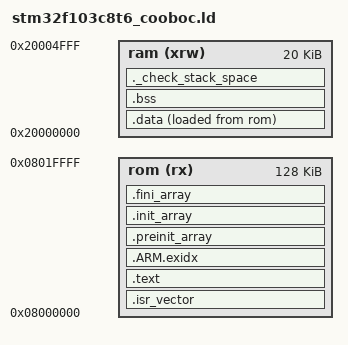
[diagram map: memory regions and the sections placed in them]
/*
* STM32 Discovery Linker Script
*/



ENTRY(Reset_Handler)

MEMORY
{
  rom (rx)      : ORIGIN = 0x08000000, LENGTH = 128K
  ram (xrw)     : ORIGIN = 0x20000000, LENGTH = 20K
}

_estack = 0x20005000;    /* bottom of 20k sram */
/*_estack = ORIGIN(RAM)+LENGTH(RAM);*/
_minimum_stack_size = 0x100; /* 256 bytes miniumum stack size */

SECTIONS
{
    /* Reset and ISR vectors */
    .isr_vector :
    {
        __isr_vector_start__ = .;
        KEEP(*(.isr_vector)) /* without 'KEEP' the garbage collector discards this section */
        ASSERT(. != __isr_vector_start__, "The .isr_vector section is empty");
    } >rom

    /*text sction, code and read only data */
  .text :
  {
    KEEP(*(.isr_vector))
    *(.text)           /* .text sections (code) */
    *(.text*)          /* .text* sections (code) */
    *(.rodata)         /* .rodata sections (constants, strings, etc.) */
    *(.rodata*)        /* .rodata* sections (constants, strings, etc.) */
    . = ALIGN(4);
    KEEP (*(.init))
    KEEP (*(.fini))
    . = ALIGN(4);
  } >rom

   /* .ARM.exidx is sorted, so has to go in its own output section.*/
   .ARM.exidx : {
        __exidx_start = .;
        *(.ARM.exidx* .gnu.linkonce.armexidx.*)
        __exidx_end = .;
    } >rom

    /*
     * Newlib and Eglibc (at least) need these for C++ support.
     *
     * (Copied from Sourcery CodeBench Lite: arm-none-eabi-gcc -V)
     */
    .preinit_array :
    {
        PROVIDE_HIDDEN(__preinit_array_start = .);
        KEEP(*(.preinit_array*))
        PROVIDE_HIDDEN(__preinit_array_end = .);
    } >rom
    .init_array :
    {
        PROVIDE_HIDDEN(__init_array_start = .);
        KEEP(*(SORT(.init_array.*)))
        KEEP(*(.init_array*))
        PROVIDE_HIDDEN(__init_array_end = .);
    } >rom
    .fini_array :
    {
        PROVIDE_HIDDEN(__fini_array_start = .);
        KEEP(*(SORT(.fini_array.*)))
        KEEP(*(.fini_array*))
        PROVIDE_HIDDEN(__fini_array_end = .);
    } >rom


    _sidata = .;         /* global needed for startup_stm3210x_md_vl.S */  

  /*now start ram area with initialized data section */
  .data :
  {   
    _sdata = .;        /* global needed for startup_stm3210x_md_vl.S */
    *(.data)          
    *(.data*)         
    . = ALIGN(4);
    _edata = .;        /* global needed for startup_stm3210x_md_vl.S */
  } >ram AT>rom

  /* uninitialized data section bss*/
  .bss :
  {
      . = ALIGN(4);
    _sbss = .;         /* global needed for startup_stm3210x_md_vl.S */
    *(.bss)
    *(.bss*)
    *(COMMON)
    . = ALIGN(4);
    _ebss = .;        /* global needed for startup_stm3210x_md_vl.S */
  } >ram

 
  /* Generates an error if minimum stack size is not left in ram */
  ._check_stack_space :
  {
    . = ALIGN(4);
    . = . + _minimum_stack_size;
    . = ALIGN(4);
  } >ram

  .ARM.attributes 0 : { KEEP (*(.ARM.attributes)) }

  /* Remove debug information from the standard libraries */
  /DISCARD/ : {
      *(.note.GNU-stack)
    libc.a ( * )
    libgcc.a ( * )
    libm.a ( * )
}
}
